# haltium_sysctrl register map
Vendor: Nordic Semiconductor; Series: nRFHaltium; File version: 1
Registers are 32-bit, read-write, reset 0x0 unless marked. A register's access mark holds for its fields unless they carry their own. Offsets are from the block's base; [hi:lo] are bit positions; lines under a group give offsets from that group; {n}, {i} and the like mark numbered series; 'fields as' and 'values as' point back to an identical list.

## LFRC_S — LFRC
Base 0x5F951000
0x00 TASKS_START wo — Start the RC oscillator
  [0] TASKS_START
    1=Trigger task
0x04 TASKS_STOP wo — Stop the RC oscillator
  [0] TASKS_STOP
    1=Trigger task
0x08 TASKS_CAL wo — Start the calibration of RC oscillator
  [0] TASKS_CAL
    1=Trigger task
0x0C TASKS_CANCELCAL wo — Cancel the calibration
  [0] TASKS_CANCELCAL
    1=Trigger task
0x100 EVENTS_STARTED — Oscillator started
  [0] EVENTS_STARTED
    0=NotGenerated (Event not generated); 1=Generated (Event generated)
0x104 EVENTS_STOPPED — Oscillator stopped
  [0] EVENTS_STOPPED
    values as EVENTS_STARTED.EVENTS_STARTED
0x108 EVENTS_CALDONE — Calibration done
  [0] EVENTS_CALDONE
    values as EVENTS_STARTED.EVENTS_STARTED
0x10C EVENTS_TRIMDONE — Trim done
  [0] EVENTS_TRIMDONE
    values as EVENTS_STARTED.EVENTS_STARTED
0x110 EVENTS_TRIMERROR — Trim error
  [0] EVENTS_TRIMERROR
    values as EVENTS_STARTED.EVENTS_STARTED
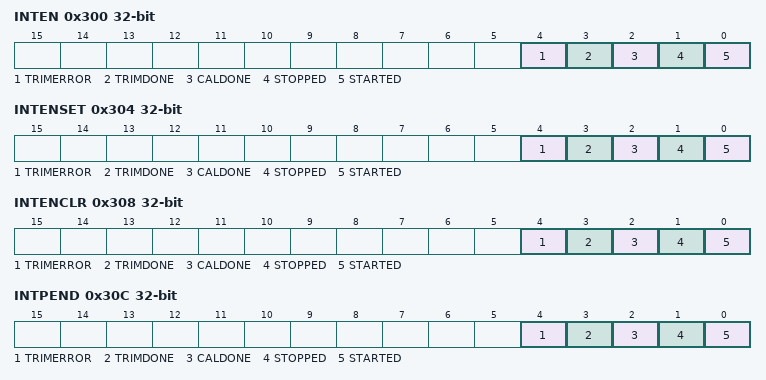
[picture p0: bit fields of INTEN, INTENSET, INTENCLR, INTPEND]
0x300 INTEN — Enable or disable interrupt
  [all] fields
    0=Disabled; 1=Enabled
  [4] TRIMERROR — Enable or disable interrupt for event TRIMERROR
  [3] TRIMDONE — Enable or disable interrupt for event TRIMDONE
  [2] CALDONE — Enable or disable interrupt for event CALDONE
  [1] STOPPED — Enable or disable interrupt for event STOPPED
  [0] STARTED — Enable or disable interrupt for event STARTED
0x304 INTENSET — Enable interrupt
  [all] fields
    on read: 0=Disabled (Read: Disabled); 1=Enabled (Read: Enabled) | on write: 1=Set (Enable)
  [4] TRIMERROR — Write '1' to enable interrupt for event TRIMERROR
  [3] TRIMDONE — Write '1' to enable interrupt for event TRIMDONE
  [2] CALDONE — Write '1' to enable interrupt for event CALDONE
  [1] STOPPED — Write '1' to enable interrupt for event STOPPED
  [0] STARTED — Write '1' to enable interrupt for event STARTED
0x308 INTENCLR — Disable interrupt
  [all] fields
    on read: 0=Disabled (Read: Disabled); 1=Enabled (Read: Enabled) | on write: 1=Clear (Disable)
  [4] TRIMERROR — Write '1' to disable interrupt for event TRIMERROR
  [3] TRIMDONE — Write '1' to disable interrupt for event TRIMDONE
  [2] CALDONE — Write '1' to disable interrupt for event CALDONE
  [1] STOPPED — Write '1' to disable interrupt for event STOPPED
  [0] STARTED — Write '1' to disable interrupt for event STARTED
0x30C INTPEND ro — Pending interrupts
  [all] fields
    on read: 0=NotPending (Read: Not pending); 1=Pending (Read: Pending)
  [4] TRIMERROR — Read pending status of interrupt for event TRIMERROR
  [3] TRIMDONE — Read pending status of interrupt for event TRIMDONE
  [2] CALDONE — Read pending status of interrupt for event CALDONE
  [1] STOPPED — Read pending status of interrupt for event STOPPED
  [0] STARTED — Read pending status of interrupt for event STARTED
0x400 CAL group — Unspecified
  0x00 LENGTH reset 0x2 — Measurement cycle count length used while calibration
    [2:0] LENGTH — Number of cycles
      0=N64 (64 cycles); 1=N128 (128 cycles); 2=N256 (256 cycles); 3=N512 (512 cycles)
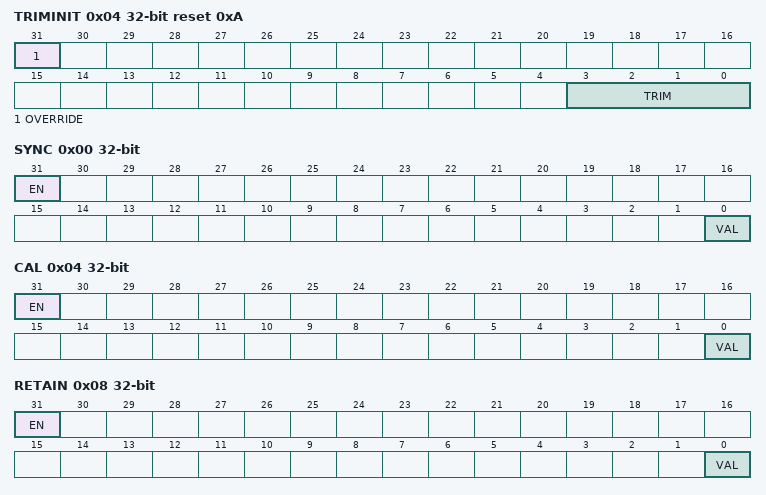
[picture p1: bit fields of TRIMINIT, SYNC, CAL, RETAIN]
  0x04 TRIMINIT reset 0xA — Initial coarse TRIM value for the oscillator.
    [31] OVERRIDE — Override the trim value
      0=Disabled (Trim override is disabled); 1=Enabled (Trim override is enabled)
    [3:0] TRIM — TRIM value
  0x08 TRIMLIMITLO — Lower trim limit
    [17:0] VALUE — TRIM limit value.
  0x0C TRIMLIMITHI reset 0x3FFFF — Higher trim limit
    [17:0] VALUE — TRIM limit value
  {0x10+4j} RESULT[{j}] (j=0..1) ro — Description collection: Calibration result from CAL=n
    [31:0] RESULT — The result in 16MHz clock cycles
  0x18 NHI ro — Number of cycles when the CAL signal is high
    [11:0] NHI — Number of cycles
0x41C OVERRIDE group — Unspecified
  0x00 SYNC — Override the SYNC signal to the LFRC32K analog module
    [31] EN — Enable the override
      0=Disabled (Override is disabled); 1=Enabled (Override is enabled)
    [0] VAL — Override value for the signal
  0x04 CAL — Override the CAL signal to the LFRC32K analog module
    fields as OVERRIDE.SYNC
  0x08 RETAIN — Override the RETAIN signal to the LFRC32K analog module
    fields as OVERRIDE.SYNC
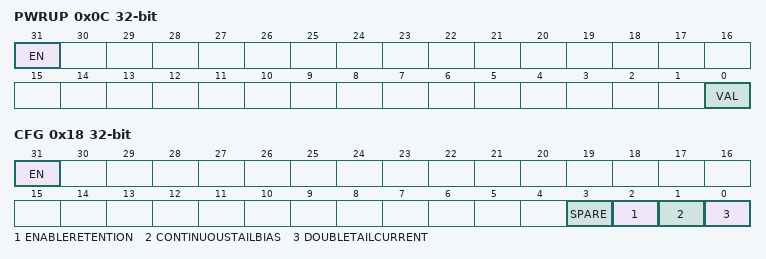
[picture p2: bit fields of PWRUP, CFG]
  0x0C PWRUP — Override the PWRUP signal to the LFRC32K analog module
    fields as OVERRIDE.SYNC
  0x10 READY ro — Read the READY signal from the LFRC32K analog module
    [0] VAL — Current value of the signal
  0x14 SETTLED ro — Read the SETTLED signal from the LFRC32K analog module
    [0] VAL — Current value of the signal
  0x18 CFG — Override the configuration
    [31] EN — Enable the override
      values as OVERRIDE.SYNC.EN
    [3] SPARE — Spare general purpose configuration bits. Register in NVM.
      0=Disabled; 1=Enabled
    [2] ENABLERETENTION — Enable retention for CAL
      0=Disabled; 1=Enabled
    [1] CONTINUOUSTAILBIAS — Enable continuous tail bias in comparator CMPX_INT, only for debugging purposes.
      0=Disabled; 1=Enabled
    [0] DOUBLETAILCURRENT — Double tail current in comparator CMPX_INT, only for debugging purposes.
      0=Disabled; 1=Enabled
0x600 DFT group — Unspecified
  0x00 ATE — Analog Test Bus (ATB) enable
    [1:0] ATB — ATB pin configuration
  0x04 DTE — Digital Test Bus (DTB) enable
    [3:0] DTB — DTB pin configuration.
  0x08 TCFG — Test configuration
    [1:0] DTB — DTB configuration
      0=None (No configuration); 1=Config1 (DTB configuration 1); 2=Config2 (DTB configuration 2)
